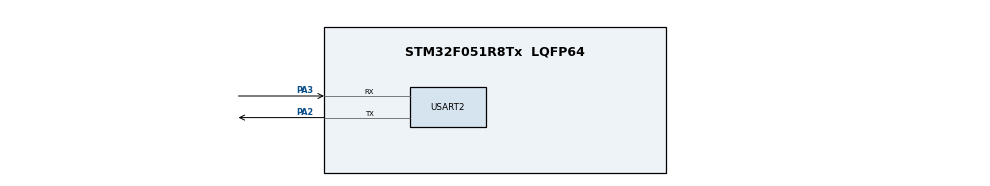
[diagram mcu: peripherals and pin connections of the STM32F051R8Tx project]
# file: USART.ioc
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Mcu.Family=STM32F0
Mcu.Name=STM32F051R8Tx
Mcu.Package=LQFP64
PA2.Mode=Asynchronous
PA2.Signal=USART2_TX
PA3.Mode=Asynchronous
PA3.Signal=USART2_RX
ProjectManager.HeapSize=0x200
ProjectManager.StackSize=0x400
ProjectManager.TargetToolchain=TrueSTUDIO
USART2.VirtualMode-Asynchronous=VM_ASYNC
board=custom

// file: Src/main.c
/* USER CODE BEGIN Header */
/**
  ******************************************************************************
  * @file           : main.c
  * @brief          : Main program body
  ******************************************************************************
  ** This notice applies to any and all portions of this file
  * that are not between comment pairs USER CODE BEGIN and
  * USER CODE END. Other portions of this file, whether
  * inserted by the user or by software development tools
  * are owned by their respective copyright owners.
  *
  * COPYRIGHT(c) 2019 STMicroelectronics
  *
  * Redistribution and use in source and binary forms, with or without modification,
  * are permitted provided that the following conditions are met:
  *   1. Redistributions of source code must retain the above copyright notice,
  *      this list of conditions and the following disclaimer.
  *   2. Redistributions in binary form must reproduce the above copyright notice,
  *      this list of conditions and the following disclaimer in the documentation
  *      and/or other materials provided with the distribution.
  *   3. Neither the name of STMicroelectronics nor the names of its contributors
  *      may be used to endorse or promote products derived from this software
  *      without specific prior written permission.
  *
  * THIS SOFTWARE IS PROVIDED BY THE COPYRIGHT HOLDERS AND CONTRIBUTORS "AS IS"
  * AND ANY EXPRESS OR IMPLIED WARRANTIES, INCLUDING, BUT NOT LIMITED TO, THE
  * IMPLIED WARRANTIES OF MERCHANTABILITY AND FITNESS FOR A PARTICULAR PURPOSE ARE
  * DISCLAIMED. IN NO EVENT SHALL THE COPYRIGHT HOLDER OR CONTRIBUTORS BE LIABLE
  * FOR ANY DIRECT, INDIRECT, INCIDENTAL, SPECIAL, EXEMPLARY, OR CONSEQUENTIAL
  * DAMAGES (INCLUDING, BUT NOT LIMITED TO, PROCUREMENT OF SUBSTITUTE GOODS OR
  * SERVICES; LOSS OF USE, DATA, OR PROFITS; OR BUSINESS INTERRUPTION) HOWEVER
  * CAUSED AND ON ANY THEORY OF LIABILITY, WHETHER IN CONTRACT, STRICT LIABILITY,
  * OR TORT (INCLUDING NEGLIGENCE OR OTHERWISE) ARISING IN ANY WAY OUT OF THE USE
  * OF THIS SOFTWARE, EVEN IF ADVISED OF THE POSSIBILITY OF SUCH DAMAGE.
  *
  ******************************************************************************
  */
/* USER CODE END Header */

#include "main.h"
#include "log.h"

void SystemClock_Config(void);
static void MX_GPIO_Init(void);
static void MX_USART2_UART_Init(void);

/* USER CODE BEGIN 0 */
void HTV_STM_LOG_0(char buffer[200])
{
	char temp[200];
	uint32_t len;
	len = sprintf(temp,buffer);
	HAL_UART_Transmit(&huart2, (uint8_t*)temp, len, 500);
}
void HTV_STM_LOG_1(char buffer[200],uint32_t parameter)
{
	char temp[200];
	uint32_t len;
	len = sprintf(temp,buffer,parameter);
	HAL_UART_Transmit(&huart2, (uint8_t*)temp, len, 500);
}
void HTV_STM_LOG_2(char buffer[200],uint32_t parameter_1,uint32_t parameter_2)
{
	char temp[200];
	uint32_t len;
	len = sprintf(temp,buffer,parameter_1,parameter_2);
	HAL_UART_Transmit(&huart2, (uint8_t*)temp, len, 500);

}

/* USER CODE END 0 */

int main(void)
{
  /* USER CODE BEGIN 1 */
/**
  * @brief  Retargets the C library printf function to the USART.
  * @param  None
  * @retval None
  */
  /* USER CODE END 1 */

  /* MCU Configuration--------------------------------------------------------*/

  /* Reset of all peripherals, Initializes the Flash interface and the Systick. */
  HAL_Init();

  /* Configure the system clock */
  SystemClock_Config();

  /* Initialize all configured peripherals */
  MX_GPIO_Init();
  MX_USART2_UART_Init();

  /* Infinite loop */
  /* USER CODE BEGIN WHILE */
  printf("\n\r welcome to www.waveshere.com !!!\n\r");
  HAL_Delay(1000);
  while (1)
  {
    /* USER CODE END WHILE */
	  HTV_STM_LOG_0("Hello World I AM HOAITV");
      printf("\n\r welcome to www.waveshere.com !!!\n\r");
      HAL_Delay(1000);
  }
}

void SystemClock_Config(void)
{
  RCC_OscInitTypeDef RCC_OscInitStruct = {0};
  RCC_ClkInitTypeDef RCC_ClkInitStruct = {0};

  /**Initializes the CPU, AHB and APB busses clocks
  */
  RCC_OscInitStruct.OscillatorType = RCC_OSCILLATORTYPE_HSI;
  RCC_OscInitStruct.HSIState = RCC_HSI_ON;
  RCC_OscInitStruct.HSICalibrationValue = RCC_HSICALIBRATION_DEFAULT;
  RCC_OscInitStruct.PLL.PLLState = RCC_PLL_NONE;
  if (HAL_RCC_OscConfig(&RCC_OscInitStruct) != HAL_OK)
  {
    Error_Handler();
  }
  /**Initializes the CPU, AHB and APB busses clocks
  */
  RCC_ClkInitStruct.ClockType = RCC_CLOCKTYPE_HCLK|RCC_CLOCKTYPE_SYSCLK
                              |RCC_CLOCKTYPE_PCLK1;
  RCC_ClkInitStruct.SYSCLKSource = RCC_SYSCLKSOURCE_HSI;
  RCC_ClkInitStruct.AHBCLKDivider = RCC_SYSCLK_DIV1;
  RCC_ClkInitStruct.APB1CLKDivider = RCC_HCLK_DIV1;

  if (HAL_RCC_ClockConfig(&RCC_ClkInitStruct, FLASH_LATENCY_0) != HAL_OK)
  {
    Error_Handler();
  }
}

static void MX_USART2_UART_Init(void)
{

  huart2.Instance = USART2;
  huart2.Init.BaudRate = 38400;
  huart2.Init.WordLength = UART_WORDLENGTH_8B;
  huart2.Init.StopBits = UART_STOPBITS_1;
  huart2.Init.Parity = UART_PARITY_NONE;
  huart2.Init.Mode = UART_MODE_TX_RX;
  huart2.Init.HwFlowCtl = UART_HWCONTROL_NONE;
  huart2.Init.OverSampling = UART_OVERSAMPLING_16;
  huart2.Init.OneBitSampling = UART_ONE_BIT_SAMPLE_DISABLE;
  huart2.AdvancedInit.AdvFeatureInit = UART_ADVFEATURE_NO_INIT;
  if (HAL_UART_Init(&huart2) != HAL_OK)
  {
    Error_Handler();
  }

}

static void MX_GPIO_Init(void)
{

  /* GPIO Ports Clock Enable */
  __HAL_RCC_GPIOA_CLK_ENABLE();

}

void Error_Handler(void)
{
}

/************************ (C) COPYRIGHT STMicroelectronics *****END OF FILE****/
